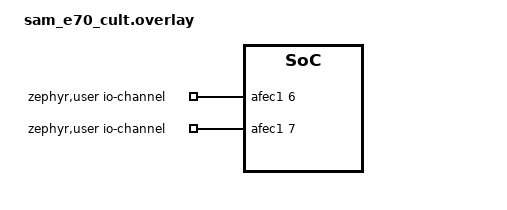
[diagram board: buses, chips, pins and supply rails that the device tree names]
/*
 * SPDX-FileCopyrightText: Copyright The Zephyr Project Contributors
 *
 * SPDX-License-Identifier: Apache-2.0
 */

/* Arduino A0 (AFEC1 AD6) and A1 (AFEC1 AD7); the test uses a single ADC device */
/ {
	zephyr,user {
		io-channels = <&afec1 6>, <&afec1 7>;
	};
};

&afec1 {
	#address-cells = <1>;
	#size-cells = <0>;

	channel@6 {
		reg = <6>;
		zephyr,gain = "ADC_GAIN_1";
		zephyr,reference = "ADC_REF_EXTERNAL0";
		zephyr,acquisition-time = <ADC_ACQ_TIME_DEFAULT>;
		zephyr,resolution = <12>;
	};

	channel@7 {
		reg = <7>;
		zephyr,gain = "ADC_GAIN_1";
		zephyr,reference = "ADC_REF_EXTERNAL0";
		zephyr,acquisition-time = <ADC_ACQ_TIME_DEFAULT>;
		zephyr,resolution = <12>;
	};
};
